# COMPUTE_CLUSTER0_MSMC_ECC_AGGR1 register map
Vendor: Texas Instruments
Peripheral module from a debugger description file (folder J7ES).
Registers are 32-bit, access not given, reset 0x0 unless marked. A register's access mark holds for its fields unless they carry their own. Offsets are as the file gives them; lines under a group give offsets from that group; [hi:lo] are bit positions; {n}, {i} and the like mark numbered series; 'fields as' and 'values as' point back to an identical list; <NAME> marks a mode.

## COMPUTE_CLUSTER0_MSMC_ECC_AGGR1
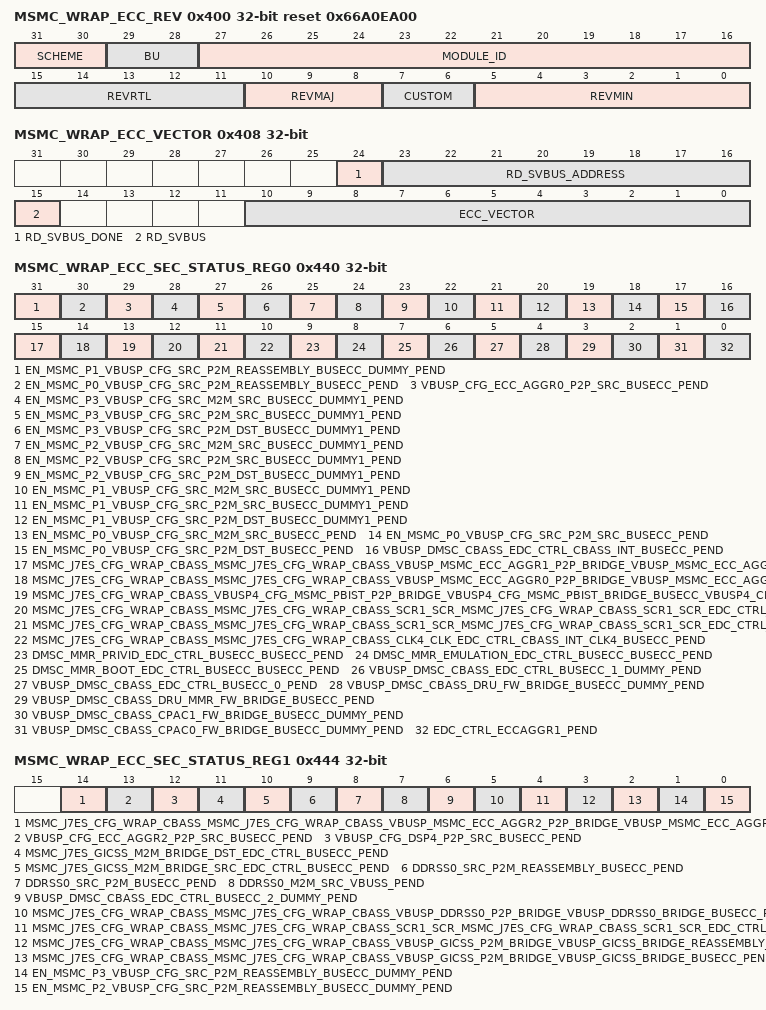
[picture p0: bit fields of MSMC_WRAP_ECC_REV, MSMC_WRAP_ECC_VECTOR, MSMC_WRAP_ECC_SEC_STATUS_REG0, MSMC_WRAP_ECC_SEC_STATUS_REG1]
0x400 MSMC_WRAP_ECC_REV ro reset 0x66A0EA00 — Revision parameters
  [31:30] SCHEME
  [29:28] BU
  [27:16] MODULE_ID
  [15:11] REVRTL — RTL version
  [10:8] REVMAJ — Major version
  [7:6] CUSTOM — Custom version
  [5:0] REVMIN — Minor version
0x408 MSMC_WRAP_ECC_VECTOR — ECC Vector Register
  [24] RD_SVBUS_DONE — Status to indicate if read on serial VBUS is complete, write of any value will clear this bit. (access RW1C)
  [23:16] RD_SVBUS_ADDRESS rw — Read address
  [15] RD_SVBUS — Write 1 to trigger a read on the serial VBUS (access RW1S)
  [10:0] ECC_VECTOR rw — Value written to select the corresponding ECC RAM for control or status
0x40C MSMC_WRAP_ECC_STAT ro reset 0x2F — Misc Status
  [10:0] NUM_RAMS — Indicates the number of RAMS serviced by the ECC aggregator
0x410 MSMC_WRAP_ECC_RESERVED_SVBUS_y rw — Reference other documents that contain the ECC RAM wrapper and EDC controller serial vbus register sets. Offset = 410h + (y * 4h); where y = 0h to 7h
  [31:0] DATA — Serial VBUS register data
0x43C MSMC_WRAP_ECC_SEC_EOI_REG — EOI Register The EOI register is used to re-trigger the pulse interrupt signal to ensure that any nested interrupt events are serviced. The software interrupt handler must write to the EOI register at the end of the current interrupt processing routine, so that new events can re-trigger the pulse interrupt signal again. For level interrupt signals the EOI register is not functional and must not be used.
  [0] EOI_WR — EOI Register (access RW1S)
0x440 MSMC_WRAP_ECC_SEC_STATUS_REG0 — Interrupt Status Register 0
  [31] EN_MSMC_P1_VBUSP_CFG_SRC_P2M_REASSEMBLY_BUSECC_DUMMY_PEND — Interrupt Pending Status for en_msmc_p1_vbusp_cfg_src_p2m_reassembly_busecc_dummy_pend (access RW1S)
  [30] EN_MSMC_P0_VBUSP_CFG_SRC_P2M_REASSEMBLY_BUSECC_PEND — Interrupt Pending Status for en_msmc_p0_vbusp_cfg_src_p2m_reassembly_busecc_pend (access RW1S)
  [29] VBUSP_CFG_ECC_AGGR0_P2P_SRC_BUSECC_PEND — Interrupt Pending Status for vbusp_cfg_ecc_aggr0_p2p_src_busecc_pend (access RW1S)
  [28] EN_MSMC_P3_VBUSP_CFG_SRC_M2M_SRC_BUSECC_DUMMY1_PEND — Interrupt Pending Status for en_msmc_p3_vbusp_cfg_src_m2m_src_busecc_dummy1_pend (access RW1S)
  [27] EN_MSMC_P3_VBUSP_CFG_SRC_P2M_SRC_BUSECC_DUMMY1_PEND — Interrupt Pending Status for en_msmc_p3_vbusp_cfg_src_p2m_src_busecc_dummy1_pend (access RW1S)
  [26] EN_MSMC_P3_VBUSP_CFG_SRC_P2M_DST_BUSECC_DUMMY1_PEND — Interrupt Pending Status for en_msmc_p3_vbusp_cfg_src_p2m_dst_busecc_dummy1_pend (access RW1S)
  [25] EN_MSMC_P2_VBUSP_CFG_SRC_M2M_SRC_BUSECC_DUMMY1_PEND — Interrupt Pending Status for en_msmc_p2_vbusp_cfg_src_m2m_src_busecc_dummy1_pend (access RW1S)
  [24] EN_MSMC_P2_VBUSP_CFG_SRC_P2M_SRC_BUSECC_DUMMY1_PEND — Interrupt Pending Status for en_msmc_p2_vbusp_cfg_src_p2m_src_busecc_dummy1_pend (access RW1S)
  [23] EN_MSMC_P2_VBUSP_CFG_SRC_P2M_DST_BUSECC_DUMMY1_PEND — Interrupt Pending Status for en_msmc_p2_vbusp_cfg_src_p2m_dst_busecc_dummy1_pend (access RW1S)
  [22] EN_MSMC_P1_VBUSP_CFG_SRC_M2M_SRC_BUSECC_DUMMY1_PEND — Interrupt Pending Status for en_msmc_p1_vbusp_cfg_src_m2m_src_busecc_dummy1_pend (access RW1S)
  [21] EN_MSMC_P1_VBUSP_CFG_SRC_P2M_SRC_BUSECC_DUMMY1_PEND — Interrupt Pending Status for en_msmc_p1_vbusp_cfg_src_p2m_src_busecc_dummy1_pend (access RW1S)
  [20] EN_MSMC_P1_VBUSP_CFG_SRC_P2M_DST_BUSECC_DUMMY1_PEND — Interrupt Pending Status for en_msmc_p1_vbusp_cfg_src_p2m_dst_busecc_dummy1_pend (access RW1S)
  [19] EN_MSMC_P0_VBUSP_CFG_SRC_M2M_SRC_BUSECC_PEND — Interrupt Pending Status for en_msmc_p0_vbusp_cfg_src_m2m_src_busecc_pend (access RW1S)
  [18] EN_MSMC_P0_VBUSP_CFG_SRC_P2M_SRC_BUSECC_PEND — Interrupt Pending Status for en_msmc_p0_vbusp_cfg_src_p2m_src_busecc_pend (access RW1S)
  [17] EN_MSMC_P0_VBUSP_CFG_SRC_P2M_DST_BUSECC_PEND — Interrupt Pending Status for en_msmc_p0_vbusp_cfg_src_p2m_dst_busecc_pend (access RW1S)
  [16] VBUSP_DMSC_CBASS_EDC_CTRL_CBASS_INT_BUSECC_PEND — Interrupt Pending Status for vbusp_dmsc_cbass_edc_ctrl_cbass_int_busecc_pend (access RW1S)
  [15] MSMC_J7ES_CFG_WRAP_CBASS_MSMC_J7ES_CFG_WRAP_CBASS_VBUSP_MSMC_ECC_AGGR1_P2P_BRIDGE_VBUSP_MSMC_ECC_AGGR1_BRIDGE_BUSECC_PEND — Interrupt Pending Status for msmc_cfg_wrap_cbass_msmc_cfg_wrap_cbass_vbusp_msmc_ecc_aggr1_p2p_bridge_vbusp_msmc_ecc_aggr1_bridge_busecc_pend (access RW1S)
  [14] MSMC_J7ES_CFG_WRAP_CBASS_MSMC_J7ES_CFG_WRAP_CBASS_VBUSP_MSMC_ECC_AGGR0_P2P_BRIDGE_VBUSP_MSMC_ECC_AGGR0_BRIDGE_BUSECC_PEND — Interrupt Pending Status for msmc_cfg_wrap_cbass_msmc_cfg_wrap_cbass_vbusp_msmc_ecc_aggr0_p2p_bridge_vbusp_msmc_ecc_aggr0_bridge_busecc_pend (access RW1S)
  [13] MSMC_J7ES_CFG_WRAP_CBASS_VBUSP4_CFG_MSMC_PBIST_P2P_BRIDGE_VBUSP4_CFG_MSMC_PBIST_BRIDGE_BUSECC_VBUSP4_CFG_MSMC_PBIST_BRIDGE_BUSECC_DUMMY_PEND — Interrupt Pending Status for msmc_cfg_wrap_cbass_vbusp4_cfg_msmc_pbist_p2p_bridge_vbusp4_cfg_msmc_pbist_bridge_busecc_vbusp4_cfg_msmc_pbist_bridge_busecc_dummy_pend (access RW1S)
  [12] MSMC_J7ES_CFG_WRAP_CBASS_MSMC_J7ES_CFG_WRAP_CBASS_SCR1_SCR_MSMC_J7ES_CFG_WRAP_CBASS_SCR1_SCR_EDC_CTRL_BUSECC_1_DUMMY_PEND — Interrupt Pending Status for msmc_cfg_wrap_cbass_msmc_cfg_wrap_cbass_scr1_scr_msmc_cfg_wrap_cbass_scr1_scr_edc_ctrl_busecc_1_dummy_pend (access RW1S)
  [11] MSMC_J7ES_CFG_WRAP_CBASS_MSMC_J7ES_CFG_WRAP_CBASS_SCR1_SCR_MSMC_J7ES_CFG_WRAP_CBASS_SCR1_SCR_EDC_CTRL_BUSECC_PEND — Interrupt Pending Status for msmc_cfg_wrap_cbass_msmc_cfg_wrap_cbass_scr1_scr_msmc_cfg_wrap_cbass_scr1_scr_edc_ctrl_busecc_pend (access RW1S)
  [10] MSMC_J7ES_CFG_WRAP_CBASS_MSMC_J7ES_CFG_WRAP_CBASS_CLK4_CLK_EDC_CTRL_CBASS_INT_CLK4_BUSECC_PEND — Interrupt Pending Status for msmc_cfg_wrap_cbass_msmc_cfg_wrap_cbass_clk4_clk_edc_ctrl_cbass_int_clk4_busecc_pend (access RW1S)
  [9] DMSC_MMR_PRIVID_EDC_CTRL_BUSECC_BUSECC_PEND — Interrupt Pending Status for dmsc_mmr_privid_edc_ctrl_busecc_busecc_pend (access RW1S)
  [8] DMSC_MMR_EMULATION_EDC_CTRL_BUSECC_BUSECC_PEND — Interrupt Pending Status for dmsc_mmr_emulation_edc_ctrl_busecc_busecc_pend (access RW1S)
  [7] DMSC_MMR_BOOT_EDC_CTRL_BUSECC_BUSECC_PEND — Interrupt Pending Status for dmsc_mmr_boot_edc_ctrl_busecc_busecc_pend (access RW1S)
  [6] VBUSP_DMSC_CBASS_EDC_CTRL_BUSECC_1_DUMMY_PEND — Interrupt Pending Status for vbusp_dmsc_cbass_edc_ctrl_busecc_1_dummy_pend (access RW1S)
  [5] VBUSP_DMSC_CBASS_EDC_CTRL_BUSECC_0_PEND — Interrupt Pending Status for vbusp_dmsc_cbass_edc_ctrl_busecc_0_pend (access RW1S)
  [4] VBUSP_DMSC_CBASS_DRU_FW_BRIDGE_BUSECC_DUMMY_PEND — Interrupt Pending Status for vbusp_dmsc_cbass_dru_fw_bridge_busecc_dummy_pend (access RW1S)
  [3] VBUSP_DMSC_CBASS_DRU_MMR_FW_BRIDGE_BUSECC_PEND — Interrupt Pending Status for vbusp_dmsc_cbass_dru_mmr_fw_bridge_busecc_pend (access RW1S)
  [2] VBUSP_DMSC_CBASS_CPAC1_FW_BRIDGE_BUSECC_DUMMY_PEND — Interrupt Pending Status for vbusp_dmsc_cbass_cpac1_fw_bridge_busecc_dummy_pend (access RW1S)
  [1] VBUSP_DMSC_CBASS_CPAC0_FW_BRIDGE_BUSECC_DUMMY_PEND — Interrupt Pending Status for vbusp_dmsc_cbass_cpac0_fw_bridge_busecc_dummy_pend (access RW1S)
  [0] EDC_CTRL_ECCAGGR1_PEND — Interrupt Pending Status for edc_ctrl_eccaggr1_pend (access RW1S)
0x444 MSMC_WRAP_ECC_SEC_STATUS_REG1 — Interrupt Status Register 1
  [14] MSMC_J7ES_CFG_WRAP_CBASS_MSMC_J7ES_CFG_WRAP_CBASS_VBUSP_MSMC_ECC_AGGR2_P2P_BRIDGE_VBUSP_MSMC_ECC_AGGR2_BRIDGE_BUSECC_PEND — Interrupt Pending Status for msmc_cfg_wrap_cbass_msmc_cfg_wrap_cbass_vbusp_msmc_ecc_aggr2_p2p_bridge_vbusp_msmc_ecc_aggr2_bridge_busecc_pend (access RW1S)
  [13] VBUSP_CFG_ECC_AGGR2_P2P_SRC_BUSECC_PEND — Interrupt Pending Status for vbusp_cfg_ecc_aggr2_p2p_src_busecc_pend (access RW1S)
  [12] VBUSP_CFG_DSP4_P2P_SRC_BUSECC_PEND — Interrupt Pending Status for vbusp_cfg_dsp4_p2p_src_busecc_pend (access RW1S)
  [11] MSMC_J7ES_GICSS_M2M_BRIDGE_DST_EDC_CTRL_BUSECC_PEND — Interrupt Pending Status for msmc_gicss_m2m_bridge_dst_edc_ctrl_busecc_pend (access RW1S)
  [10] MSMC_J7ES_GICSS_M2M_BRIDGE_SRC_EDC_CTRL_BUSECC_PEND — Interrupt Pending Status for msmc_gicss_m2m_bridge_src_edc_ctrl_busecc_pend (access RW1S)
  [9] DDRSS0_SRC_P2M_REASSEMBLY_BUSECC_PEND — Interrupt Pending Status for ddrss0_src_p2m_reassembly_busecc_pend (access RW1S)
  [8] DDRSS0_SRC_P2M_BUSECC_PEND — Interrupt Pending Status for ddrss0_src_p2m_busecc_pend (access RW1S)
  [7] DDRSS0_M2M_SRC_VBUSS_PEND — Interrupt Pending Status for ddrss0_m2m_src_vbuss_pend (access RW1S)
  [6] VBUSP_DMSC_CBASS_EDC_CTRL_BUSECC_2_DUMMY_PEND — Interrupt Pending Status for vbusp_dmsc_cbass_edc_ctrl_busecc_2_dummy_pend (access RW1S)
  [5] MSMC_J7ES_CFG_WRAP_CBASS_MSMC_J7ES_CFG_WRAP_CBASS_VBUSP_DDRSS0_P2P_BRIDGE_VBUSP_DDRSS0_BRIDGE_BUSECC_PEND — Interrupt Pending Status for msmc_cfg_wrap_cbass_msmc_cfg_wrap_cbass_vbusp_ddrss0_p2p_bridge_vbusp_ddrss0_bridge_busecc_pend (access RW1S)
  [4] MSMC_J7ES_CFG_WRAP_CBASS_MSMC_J7ES_CFG_WRAP_CBASS_SCR1_SCR_MSMC_J7ES_CFG_WRAP_CBASS_SCR1_SCR_EDC_CTRL_BUSECC_2_DUMMY_PEND — Interrupt Pending Status for msmc_cfg_wrap_cbass_msmc_cfg_wrap_cbass_scr1_scr_msmc_cfg_wrap_cbass_scr1_scr_edc_ctrl_busecc_2_dummy_pend (access RW1S)
  [3] MSMC_J7ES_CFG_WRAP_CBASS_MSMC_J7ES_CFG_WRAP_CBASS_VBUSP_GICSS_P2M_BRIDGE_VBUSP_GICSS_BRIDGE_REASSEMBLY_BUSECC_PEND — Interrupt Pending Status for msmc_cfg_wrap_cbass_msmc_cfg_wrap_cbass_vbusp_gicss_p2m_bridge_vbusp_gicss_bridge_reassembly_busecc_pend (access RW1S)
  [2] MSMC_J7ES_CFG_WRAP_CBASS_MSMC_J7ES_CFG_WRAP_CBASS_VBUSP_GICSS_P2M_BRIDGE_VBUSP_GICSS_BRIDGE_BUSECC_PEND — Interrupt Pending Status for msmc_cfg_wrap_cbass_msmc_cfg_wrap_cbass_vbusp_gicss_p2m_bridge_vbusp_gicss_bridge_busecc_pend (access RW1S)
  [1] EN_MSMC_P3_VBUSP_CFG_SRC_P2M_REASSEMBLY_BUSECC_DUMMY_PEND — Interrupt Pending Status for en_msmc_p3_vbusp_cfg_src_p2m_reassembly_busecc_dummy_pend (access RW1S)
  [0] EN_MSMC_P2_VBUSP_CFG_SRC_P2M_REASSEMBLY_BUSECC_DUMMY_PEND — Interrupt Pending Status for en_msmc_p2_vbusp_cfg_src_p2m_reassembly_busecc_dummy_pend (access RW1S)
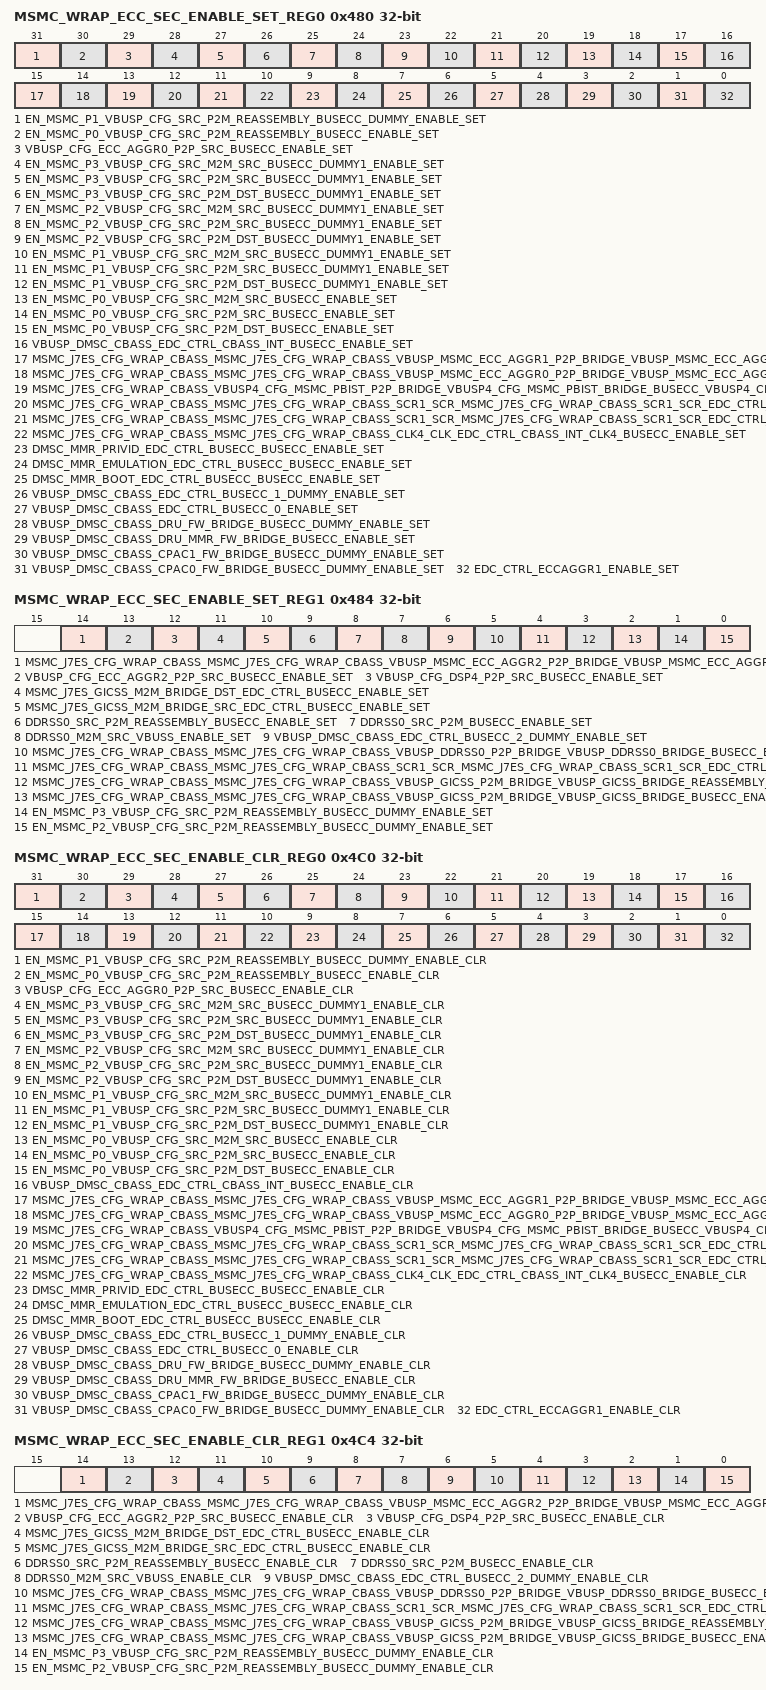
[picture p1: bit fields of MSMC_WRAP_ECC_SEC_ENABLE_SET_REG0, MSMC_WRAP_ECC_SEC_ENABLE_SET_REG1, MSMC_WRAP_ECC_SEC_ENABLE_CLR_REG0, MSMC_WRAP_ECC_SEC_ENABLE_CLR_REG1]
0x480 MSMC_WRAP_ECC_SEC_ENABLE_SET_REG0 — Interrupt Enable Set Register 0
  [31] EN_MSMC_P1_VBUSP_CFG_SRC_P2M_REASSEMBLY_BUSECC_DUMMY_ENABLE_SET — Interrupt Enable Set Register for en_msmc_p1_vbusp_cfg_src_p2m_reassembly_busecc_dummy_pend (access RW1S)
  [30] EN_MSMC_P0_VBUSP_CFG_SRC_P2M_REASSEMBLY_BUSECC_ENABLE_SET — Interrupt Enable Set Register for en_msmc_p0_vbusp_cfg_src_p2m_reassembly_busecc_pend (access RW1S)
  [29] VBUSP_CFG_ECC_AGGR0_P2P_SRC_BUSECC_ENABLE_SET — Interrupt Enable Set Register for vbusp_cfg_ecc_aggr0_p2p_src_busecc_pend (access RW1S)
  [28] EN_MSMC_P3_VBUSP_CFG_SRC_M2M_SRC_BUSECC_DUMMY1_ENABLE_SET — Interrupt Enable Set Register for en_msmc_p3_vbusp_cfg_src_m2m_src_busecc_dummy1_pend (access RW1S)
  [27] EN_MSMC_P3_VBUSP_CFG_SRC_P2M_SRC_BUSECC_DUMMY1_ENABLE_SET — Interrupt Enable Set Register for en_msmc_p3_vbusp_cfg_src_p2m_src_busecc_dummy1_pend (access RW1S)
  [26] EN_MSMC_P3_VBUSP_CFG_SRC_P2M_DST_BUSECC_DUMMY1_ENABLE_SET — Interrupt Enable Set Register for en_msmc_p3_vbusp_cfg_src_p2m_dst_busecc_dummy1_pend (access RW1S)
  [25] EN_MSMC_P2_VBUSP_CFG_SRC_M2M_SRC_BUSECC_DUMMY1_ENABLE_SET — Interrupt Enable Set Register for en_msmc_p2_vbusp_cfg_src_m2m_src_busecc_dummy1_pend (access RW1S)
  [24] EN_MSMC_P2_VBUSP_CFG_SRC_P2M_SRC_BUSECC_DUMMY1_ENABLE_SET — Interrupt Enable Set Register for en_msmc_p2_vbusp_cfg_src_p2m_src_busecc_dummy1_pend (access RW1S)
  [23] EN_MSMC_P2_VBUSP_CFG_SRC_P2M_DST_BUSECC_DUMMY1_ENABLE_SET — Interrupt Enable Set Register for en_msmc_p2_vbusp_cfg_src_p2m_dst_busecc_dummy1_pend (access RW1S)
  [22] EN_MSMC_P1_VBUSP_CFG_SRC_M2M_SRC_BUSECC_DUMMY1_ENABLE_SET — Interrupt Enable Set Register for en_msmc_p1_vbusp_cfg_src_m2m_src_busecc_dummy1_pend (access RW1S)
  [21] EN_MSMC_P1_VBUSP_CFG_SRC_P2M_SRC_BUSECC_DUMMY1_ENABLE_SET — Interrupt Enable Set Register for en_msmc_p1_vbusp_cfg_src_p2m_src_busecc_dummy1_pend (access RW1S)
  [20] EN_MSMC_P1_VBUSP_CFG_SRC_P2M_DST_BUSECC_DUMMY1_ENABLE_SET — Interrupt Enable Set Register for en_msmc_p1_vbusp_cfg_src_p2m_dst_busecc_dummy1_pend (access RW1S)
  [19] EN_MSMC_P0_VBUSP_CFG_SRC_M2M_SRC_BUSECC_ENABLE_SET — Interrupt Enable Set Register for en_msmc_p0_vbusp_cfg_src_m2m_src_busecc_pend (access RW1S)
  [18] EN_MSMC_P0_VBUSP_CFG_SRC_P2M_SRC_BUSECC_ENABLE_SET — Interrupt Enable Set Register for en_msmc_p0_vbusp_cfg_src_p2m_src_busecc_pend (access RW1S)
  [17] EN_MSMC_P0_VBUSP_CFG_SRC_P2M_DST_BUSECC_ENABLE_SET — Interrupt Enable Set Register for en_msmc_p0_vbusp_cfg_src_p2m_dst_busecc_pend (access RW1S)
  [16] VBUSP_DMSC_CBASS_EDC_CTRL_CBASS_INT_BUSECC_ENABLE_SET — Interrupt Enable Set Register for vbusp_dmsc_cbass_edc_ctrl_cbass_int_busecc_pend (access RW1S)
  [15] MSMC_J7ES_CFG_WRAP_CBASS_MSMC_J7ES_CFG_WRAP_CBASS_VBUSP_MSMC_ECC_AGGR1_P2P_BRIDGE_VBUSP_MSMC_ECC_AGGR1_BRIDGE_BUSECC_ENABLE_SET — Interrupt Enable Set Register for msmc_cfg_wrap_cbass_msmc_cfg_wrap_cbass_vbusp_msmc_ecc_aggr1_p2p_bridge_vbusp_msmc_ecc_aggr1_bridge_busecc_pend (access RW1S)
  [14] MSMC_J7ES_CFG_WRAP_CBASS_MSMC_J7ES_CFG_WRAP_CBASS_VBUSP_MSMC_ECC_AGGR0_P2P_BRIDGE_VBUSP_MSMC_ECC_AGGR0_BRIDGE_BUSECC_ENABLE_SET — Interrupt Enable Set Register for msmc_cfg_wrap_cbass_msmc_cfg_wrap_cbass_vbusp_msmc_ecc_aggr0_p2p_bridge_vbusp_msmc_ecc_aggr0_bridge_busecc_pend (access RW1S)
  [13] MSMC_J7ES_CFG_WRAP_CBASS_VBUSP4_CFG_MSMC_PBIST_P2P_BRIDGE_VBUSP4_CFG_MSMC_PBIST_BRIDGE_BUSECC_VBUSP4_CFG_MSMC_PBIST_BRIDGE_BUSECC_DUMMY_ENABLE_SET — Interrupt Enable Set Register for msmc_cfg_wrap_cbass_vbusp4_cfg_msmc_pbist_p2p_bridge_vbusp4_cfg_msmc_pbist_bridge_busecc_vbusp4_cfg_msmc_pbist_bridge_busecc_dummy_pend (access RW1S)
  [12] MSMC_J7ES_CFG_WRAP_CBASS_MSMC_J7ES_CFG_WRAP_CBASS_SCR1_SCR_MSMC_J7ES_CFG_WRAP_CBASS_SCR1_SCR_EDC_CTRL_BUSECC_1_DUMMY_ENABLE_SET — Interrupt Enable Set Register for msmc_cfg_wrap_cbass_msmc_cfg_wrap_cbass_scr1_scr_msmc_cfg_wrap_cbass_scr1_scr_edc_ctrl_busecc_1_dummy_pend (access RW1S)
  [11] MSMC_J7ES_CFG_WRAP_CBASS_MSMC_J7ES_CFG_WRAP_CBASS_SCR1_SCR_MSMC_J7ES_CFG_WRAP_CBASS_SCR1_SCR_EDC_CTRL_BUSECC_ENABLE_SET — Interrupt Enable Set Register for msmc_cfg_wrap_cbass_msmc_cfg_wrap_cbass_scr1_scr_msmc_cfg_wrap_cbass_scr1_scr_edc_ctrl_busecc_pend (access RW1S)
  [10] MSMC_J7ES_CFG_WRAP_CBASS_MSMC_J7ES_CFG_WRAP_CBASS_CLK4_CLK_EDC_CTRL_CBASS_INT_CLK4_BUSECC_ENABLE_SET — Interrupt Enable Set Register for msmc_cfg_wrap_cbass_msmc_cfg_wrap_cbass_clk4_clk_edc_ctrl_cbass_int_clk4_busecc_pend (access RW1S)
  [9] DMSC_MMR_PRIVID_EDC_CTRL_BUSECC_BUSECC_ENABLE_SET — Interrupt Enable Set Register for dmsc_mmr_privid_edc_ctrl_busecc_busecc_pend (access RW1S)
  [8] DMSC_MMR_EMULATION_EDC_CTRL_BUSECC_BUSECC_ENABLE_SET — Interrupt Enable Set Register for dmsc_mmr_emulation_edc_ctrl_busecc_busecc_pend (access RW1S)
  [7] DMSC_MMR_BOOT_EDC_CTRL_BUSECC_BUSECC_ENABLE_SET — Interrupt Enable Set Register for dmsc_mmr_boot_edc_ctrl_busecc_busecc_pend (access RW1S)
  [6] VBUSP_DMSC_CBASS_EDC_CTRL_BUSECC_1_DUMMY_ENABLE_SET — Interrupt Enable Set Register for vbusp_dmsc_cbass_edc_ctrl_busecc_1_dummy_pend (access RW1S)
  [5] VBUSP_DMSC_CBASS_EDC_CTRL_BUSECC_0_ENABLE_SET — Interrupt Enable Set Register for vbusp_dmsc_cbass_edc_ctrl_busecc_0_pend (access RW1S)
  [4] VBUSP_DMSC_CBASS_DRU_FW_BRIDGE_BUSECC_DUMMY_ENABLE_SET — Interrupt Enable Set Register for vbusp_dmsc_cbass_dru_fw_bridge_busecc_dummy_pend (access RW1S)
  [3] VBUSP_DMSC_CBASS_DRU_MMR_FW_BRIDGE_BUSECC_ENABLE_SET — Interrupt Enable Set Register for vbusp_dmsc_cbass_dru_mmr_fw_bridge_busecc_pend (access RW1S)
  [2] VBUSP_DMSC_CBASS_CPAC1_FW_BRIDGE_BUSECC_DUMMY_ENABLE_SET — Interrupt Enable Set Register for vbusp_dmsc_cbass_cpac1_fw_bridge_busecc_dummy_pend (access RW1S)
  [1] VBUSP_DMSC_CBASS_CPAC0_FW_BRIDGE_BUSECC_DUMMY_ENABLE_SET — Interrupt Enable Set Register for vbusp_dmsc_cbass_cpac0_fw_bridge_busecc_dummy_pend (access RW1S)
  [0] EDC_CTRL_ECCAGGR1_ENABLE_SET — Interrupt Enable Set Register for edc_ctrl_eccaggr1_pend (access RW1S)
0x484 MSMC_WRAP_ECC_SEC_ENABLE_SET_REG1 — Interrupt Enable Set Register 1
  [14] MSMC_J7ES_CFG_WRAP_CBASS_MSMC_J7ES_CFG_WRAP_CBASS_VBUSP_MSMC_ECC_AGGR2_P2P_BRIDGE_VBUSP_MSMC_ECC_AGGR2_BRIDGE_BUSECC_ENABLE_SET — Interrupt Enable Set Register for msmc_cfg_wrap_cbass_msmc_cfg_wrap_cbass_vbusp_msmc_ecc_aggr2_p2p_bridge_vbusp_msmc_ecc_aggr2_bridge_busecc_pend (access RW1S)
  [13] VBUSP_CFG_ECC_AGGR2_P2P_SRC_BUSECC_ENABLE_SET — Interrupt Enable Set Register for vbusp_cfg_ecc_aggr2_p2p_src_busecc_pend (access RW1S)
  [12] VBUSP_CFG_DSP4_P2P_SRC_BUSECC_ENABLE_SET — Interrupt Enable Set Register for vbusp_cfg_dsp4_p2p_src_busecc_pend (access RW1S)
  [11] MSMC_J7ES_GICSS_M2M_BRIDGE_DST_EDC_CTRL_BUSECC_ENABLE_SET — Interrupt Enable Set Register for msmc_gicss_m2m_bridge_dst_edc_ctrl_busecc_pend (access RW1S)
  [10] MSMC_J7ES_GICSS_M2M_BRIDGE_SRC_EDC_CTRL_BUSECC_ENABLE_SET — Interrupt Enable Set Register for msmc_gicss_m2m_bridge_src_edc_ctrl_busecc_pend (access RW1S)
  [9] DDRSS0_SRC_P2M_REASSEMBLY_BUSECC_ENABLE_SET — Interrupt Enable Set Register for ddrss0_src_p2m_reassembly_busecc_pend (access RW1S)
  [8] DDRSS0_SRC_P2M_BUSECC_ENABLE_SET — Interrupt Enable Set Register for ddrss0_src_p2m_busecc_pend (access RW1S)
  [7] DDRSS0_M2M_SRC_VBUSS_ENABLE_SET — Interrupt Enable Set Register for ddrss0_m2m_src_vbuss_pend (access RW1S)
  [6] VBUSP_DMSC_CBASS_EDC_CTRL_BUSECC_2_DUMMY_ENABLE_SET — Interrupt Enable Set Register for vbusp_dmsc_cbass_edc_ctrl_busecc_2_dummy_pend (access RW1S)
  [5] MSMC_J7ES_CFG_WRAP_CBASS_MSMC_J7ES_CFG_WRAP_CBASS_VBUSP_DDRSS0_P2P_BRIDGE_VBUSP_DDRSS0_BRIDGE_BUSECC_ENABLE_SET — Interrupt Enable Set Register for msmc_cfg_wrap_cbass_msmc_cfg_wrap_cbass_vbusp_ddrss0_p2p_bridge_vbusp_ddrss0_bridge_busecc_pend (access RW1S)
  [4] MSMC_J7ES_CFG_WRAP_CBASS_MSMC_J7ES_CFG_WRAP_CBASS_SCR1_SCR_MSMC_J7ES_CFG_WRAP_CBASS_SCR1_SCR_EDC_CTRL_BUSECC_2_DUMMY_ENABLE_SET — Interrupt Enable Set Register for msmc_cfg_wrap_cbass_msmc_cfg_wrap_cbass_scr1_scr_msmc_cfg_wrap_cbass_scr1_scr_edc_ctrl_busecc_2_dummy_pend (access RW1S)
  [3] MSMC_J7ES_CFG_WRAP_CBASS_MSMC_J7ES_CFG_WRAP_CBASS_VBUSP_GICSS_P2M_BRIDGE_VBUSP_GICSS_BRIDGE_REASSEMBLY_BUSECC_ENABLE_SET — Interrupt Enable Set Register for msmc_cfg_wrap_cbass_msmc_cfg_wrap_cbass_vbusp_gicss_p2m_bridge_vbusp_gicss_bridge_reassembly_busecc_pend (access RW1S)
  [2] MSMC_J7ES_CFG_WRAP_CBASS_MSMC_J7ES_CFG_WRAP_CBASS_VBUSP_GICSS_P2M_BRIDGE_VBUSP_GICSS_BRIDGE_BUSECC_ENABLE_SET — Interrupt Enable Set Register for msmc_cfg_wrap_cbass_msmc_cfg_wrap_cbass_vbusp_gicss_p2m_bridge_vbusp_gicss_bridge_busecc_pend (access RW1S)
  [1] EN_MSMC_P3_VBUSP_CFG_SRC_P2M_REASSEMBLY_BUSECC_DUMMY_ENABLE_SET — Interrupt Enable Set Register for en_msmc_p3_vbusp_cfg_src_p2m_reassembly_busecc_dummy_pend (access RW1S)
  [0] EN_MSMC_P2_VBUSP_CFG_SRC_P2M_REASSEMBLY_BUSECC_DUMMY_ENABLE_SET — Interrupt Enable Set Register for en_msmc_p2_vbusp_cfg_src_p2m_reassembly_busecc_dummy_pend (access RW1S)
0x4C0 MSMC_WRAP_ECC_SEC_ENABLE_CLR_REG0 — Interrupt Enable Clear Register 0
  [31] EN_MSMC_P1_VBUSP_CFG_SRC_P2M_REASSEMBLY_BUSECC_DUMMY_ENABLE_CLR — Interrupt Enable Clear Register for en_msmc_p1_vbusp_cfg_src_p2m_reassembly_busecc_dummy_pend (access RW1C)
  [30] EN_MSMC_P0_VBUSP_CFG_SRC_P2M_REASSEMBLY_BUSECC_ENABLE_CLR — Interrupt Enable Clear Register for en_msmc_p0_vbusp_cfg_src_p2m_reassembly_busecc_pend (access RW1C)
  [29] VBUSP_CFG_ECC_AGGR0_P2P_SRC_BUSECC_ENABLE_CLR — Interrupt Enable Clear Register for vbusp_cfg_ecc_aggr0_p2p_src_busecc_pend (access RW1C)
  [28] EN_MSMC_P3_VBUSP_CFG_SRC_M2M_SRC_BUSECC_DUMMY1_ENABLE_CLR — Interrupt Enable Clear Register for en_msmc_p3_vbusp_cfg_src_m2m_src_busecc_dummy1_pend (access RW1C)
  [27] EN_MSMC_P3_VBUSP_CFG_SRC_P2M_SRC_BUSECC_DUMMY1_ENABLE_CLR — Interrupt Enable Clear Register for en_msmc_p3_vbusp_cfg_src_p2m_src_busecc_dummy1_pend (access RW1C)
  [26] EN_MSMC_P3_VBUSP_CFG_SRC_P2M_DST_BUSECC_DUMMY1_ENABLE_CLR — Interrupt Enable Clear Register for en_msmc_p3_vbusp_cfg_src_p2m_dst_busecc_dummy1_pend (access RW1C)
  [25] EN_MSMC_P2_VBUSP_CFG_SRC_M2M_SRC_BUSECC_DUMMY1_ENABLE_CLR — Interrupt Enable Clear Register for en_msmc_p2_vbusp_cfg_src_m2m_src_busecc_dummy1_pend (access RW1C)
  [24] EN_MSMC_P2_VBUSP_CFG_SRC_P2M_SRC_BUSECC_DUMMY1_ENABLE_CLR — Interrupt Enable Clear Register for en_msmc_p2_vbusp_cfg_src_p2m_src_busecc_dummy1_pend (access RW1C)
  [23] EN_MSMC_P2_VBUSP_CFG_SRC_P2M_DST_BUSECC_DUMMY1_ENABLE_CLR — Interrupt Enable Clear Register for en_msmc_p2_vbusp_cfg_src_p2m_dst_busecc_dummy1_pend (access RW1C)
  [22] EN_MSMC_P1_VBUSP_CFG_SRC_M2M_SRC_BUSECC_DUMMY1_ENABLE_CLR — Interrupt Enable Clear Register for en_msmc_p1_vbusp_cfg_src_m2m_src_busecc_dummy1_pend (access RW1C)
  [21] EN_MSMC_P1_VBUSP_CFG_SRC_P2M_SRC_BUSECC_DUMMY1_ENABLE_CLR — Interrupt Enable Clear Register for en_msmc_p1_vbusp_cfg_src_p2m_src_busecc_dummy1_pend (access RW1C)
  [20] EN_MSMC_P1_VBUSP_CFG_SRC_P2M_DST_BUSECC_DUMMY1_ENABLE_CLR — Interrupt Enable Clear Register for en_msmc_p1_vbusp_cfg_src_p2m_dst_busecc_dummy1_pend (access RW1C)
  [19] EN_MSMC_P0_VBUSP_CFG_SRC_M2M_SRC_BUSECC_ENABLE_CLR — Interrupt Enable Clear Register for en_msmc_p0_vbusp_cfg_src_m2m_src_busecc_pend (access RW1C)
  [18] EN_MSMC_P0_VBUSP_CFG_SRC_P2M_SRC_BUSECC_ENABLE_CLR — Interrupt Enable Clear Register for en_msmc_p0_vbusp_cfg_src_p2m_src_busecc_pend (access RW1C)
  [17] EN_MSMC_P0_VBUSP_CFG_SRC_P2M_DST_BUSECC_ENABLE_CLR — Interrupt Enable Clear Register for en_msmc_p0_vbusp_cfg_src_p2m_dst_busecc_pend (access RW1C)
  [16] VBUSP_DMSC_CBASS_EDC_CTRL_CBASS_INT_BUSECC_ENABLE_CLR — Interrupt Enable Clear Register for vbusp_dmsc_cbass_edc_ctrl_cbass_int_busecc_pend (access RW1C)
  [15] MSMC_J7ES_CFG_WRAP_CBASS_MSMC_J7ES_CFG_WRAP_CBASS_VBUSP_MSMC_ECC_AGGR1_P2P_BRIDGE_VBUSP_MSMC_ECC_AGGR1_BRIDGE_BUSECC_ENABLE_CLR — Interrupt Enable Clear Register for msmc_cfg_wrap_cbass_msmc_cfg_wrap_cbass_vbusp_msmc_ecc_aggr1_p2p_bridge_vbusp_msmc_ecc_aggr1_bridge_busecc_pend (access RW1C)
  [14] MSMC_J7ES_CFG_WRAP_CBASS_MSMC_J7ES_CFG_WRAP_CBASS_VBUSP_MSMC_ECC_AGGR0_P2P_BRIDGE_VBUSP_MSMC_ECC_AGGR0_BRIDGE_BUSECC_ENABLE_CLR — Interrupt Enable Clear Register for msmc_cfg_wrap_cbass_msmc_cfg_wrap_cbass_vbusp_msmc_ecc_aggr0_p2p_bridge_vbusp_msmc_ecc_aggr0_bridge_busecc_pend (access RW1C)
  [13] MSMC_J7ES_CFG_WRAP_CBASS_VBUSP4_CFG_MSMC_PBIST_P2P_BRIDGE_VBUSP4_CFG_MSMC_PBIST_BRIDGE_BUSECC_VBUSP4_CFG_MSMC_PBIST_BRIDGE_BUSECC_DUMMY_ENABLE_CLR — Interrupt Enable Clear Register for msmc_cfg_wrap_cbass_vbusp4_cfg_msmc_pbist_p2p_bridge_vbusp4_cfg_msmc_pbist_bridge_busecc_vbusp4_cfg_msmc_pbist_bridge_busecc_dummy_pend (access RW1C)
  [12] MSMC_J7ES_CFG_WRAP_CBASS_MSMC_J7ES_CFG_WRAP_CBASS_SCR1_SCR_MSMC_J7ES_CFG_WRAP_CBASS_SCR1_SCR_EDC_CTRL_BUSECC_1_DUMMY_ENABLE_CLR — Interrupt Enable Clear Register for msmc_cfg_wrap_cbass_msmc_cfg_wrap_cbass_scr1_scr_msmc_cfg_wrap_cbass_scr1_scr_edc_ctrl_busecc_1_dummy_pend (access RW1C)
  [11] MSMC_J7ES_CFG_WRAP_CBASS_MSMC_J7ES_CFG_WRAP_CBASS_SCR1_SCR_MSMC_J7ES_CFG_WRAP_CBASS_SCR1_SCR_EDC_CTRL_BUSECC_ENABLE_CLR — Interrupt Enable Clear Register for msmc_cfg_wrap_cbass_msmc_cfg_wrap_cbass_scr1_scr_msmc_cfg_wrap_cbass_scr1_scr_edc_ctrl_busecc_pend (access RW1C)
  [10] MSMC_J7ES_CFG_WRAP_CBASS_MSMC_J7ES_CFG_WRAP_CBASS_CLK4_CLK_EDC_CTRL_CBASS_INT_CLK4_BUSECC_ENABLE_CLR — Interrupt Enable Clear Register for msmc_cfg_wrap_cbass_msmc_cfg_wrap_cbass_clk4_clk_edc_ctrl_cbass_int_clk4_busecc_pend (access RW1C)
  [9] DMSC_MMR_PRIVID_EDC_CTRL_BUSECC_BUSECC_ENABLE_CLR — Interrupt Enable Clear Register for dmsc_mmr_privid_edc_ctrl_busecc_busecc_pend (access RW1C)
  [8] DMSC_MMR_EMULATION_EDC_CTRL_BUSECC_BUSECC_ENABLE_CLR — Interrupt Enable Clear Register for dmsc_mmr_emulation_edc_ctrl_busecc_busecc_pend (access RW1C)
  [7] DMSC_MMR_BOOT_EDC_CTRL_BUSECC_BUSECC_ENABLE_CLR — Interrupt Enable Clear Register for dmsc_mmr_boot_edc_ctrl_busecc_busecc_pend (access RW1C)
  [6] VBUSP_DMSC_CBASS_EDC_CTRL_BUSECC_1_DUMMY_ENABLE_CLR — Interrupt Enable Clear Register for vbusp_dmsc_cbass_edc_ctrl_busecc_1_dummy_pend (access RW1C)
  [5] VBUSP_DMSC_CBASS_EDC_CTRL_BUSECC_0_ENABLE_CLR — Interrupt Enable Clear Register for vbusp_dmsc_cbass_edc_ctrl_busecc_0_pend (access RW1C)
  [4] VBUSP_DMSC_CBASS_DRU_FW_BRIDGE_BUSECC_DUMMY_ENABLE_CLR — Interrupt Enable Clear Register for vbusp_dmsc_cbass_dru_fw_bridge_busecc_dummy_pend (access RW1C)
  [3] VBUSP_DMSC_CBASS_DRU_MMR_FW_BRIDGE_BUSECC_ENABLE_CLR — Interrupt Enable Clear Register for vbusp_dmsc_cbass_dru_mmr_fw_bridge_busecc_pend (access RW1C)
  [2] VBUSP_DMSC_CBASS_CPAC1_FW_BRIDGE_BUSECC_DUMMY_ENABLE_CLR — Interrupt Enable Clear Register for vbusp_dmsc_cbass_cpac1_fw_bridge_busecc_dummy_pend (access RW1C)
  [1] VBUSP_DMSC_CBASS_CPAC0_FW_BRIDGE_BUSECC_DUMMY_ENABLE_CLR — Interrupt Enable Clear Register for vbusp_dmsc_cbass_cpac0_fw_bridge_busecc_dummy_pend (access RW1C)
  [0] EDC_CTRL_ECCAGGR1_ENABLE_CLR — Interrupt Enable Clear Register for edc_ctrl_eccaggr1_pend (access RW1C)
0x4C4 MSMC_WRAP_ECC_SEC_ENABLE_CLR_REG1 — Interrupt Enable Clear Register 1
  [14] MSMC_J7ES_CFG_WRAP_CBASS_MSMC_J7ES_CFG_WRAP_CBASS_VBUSP_MSMC_ECC_AGGR2_P2P_BRIDGE_VBUSP_MSMC_ECC_AGGR2_BRIDGE_BUSECC_ENABLE_CLR — Interrupt Enable Clear Register for msmc_cfg_wrap_cbass_msmc_cfg_wrap_cbass_vbusp_msmc_ecc_aggr2_p2p_bridge_vbusp_msmc_ecc_aggr2_bridge_busecc_pend (access RW1C)
  [13] VBUSP_CFG_ECC_AGGR2_P2P_SRC_BUSECC_ENABLE_CLR — Interrupt Enable Clear Register for vbusp_cfg_ecc_aggr2_p2p_src_busecc_pend (access RW1C)
  [12] VBUSP_CFG_DSP4_P2P_SRC_BUSECC_ENABLE_CLR — Interrupt Enable Clear Register for vbusp_cfg_dsp4_p2p_src_busecc_pend (access RW1C)
  [11] MSMC_J7ES_GICSS_M2M_BRIDGE_DST_EDC_CTRL_BUSECC_ENABLE_CLR — Interrupt Enable Clear Register for msmc_gicss_m2m_bridge_dst_edc_ctrl_busecc_pend (access RW1C)
  [10] MSMC_J7ES_GICSS_M2M_BRIDGE_SRC_EDC_CTRL_BUSECC_ENABLE_CLR — Interrupt Enable Clear Register for msmc_gicss_m2m_bridge_src_edc_ctrl_busecc_pend (access RW1C)
  [9] DDRSS0_SRC_P2M_REASSEMBLY_BUSECC_ENABLE_CLR — Interrupt Enable Clear Register for ddrss0_src_p2m_reassembly_busecc_pend (access RW1C)
  [8] DDRSS0_SRC_P2M_BUSECC_ENABLE_CLR — Interrupt Enable Clear Register for ddrss0_src_p2m_busecc_pend (access RW1C)
  [7] DDRSS0_M2M_SRC_VBUSS_ENABLE_CLR — Interrupt Enable Clear Register for ddrss0_m2m_src_vbuss_pend (access RW1C)
  [6] VBUSP_DMSC_CBASS_EDC_CTRL_BUSECC_2_DUMMY_ENABLE_CLR — Interrupt Enable Clear Register for vbusp_dmsc_cbass_edc_ctrl_busecc_2_dummy_pend (access RW1C)
  [5] MSMC_J7ES_CFG_WRAP_CBASS_MSMC_J7ES_CFG_WRAP_CBASS_VBUSP_DDRSS0_P2P_BRIDGE_VBUSP_DDRSS0_BRIDGE_BUSECC_ENABLE_CLR — Interrupt Enable Clear Register for msmc_cfg_wrap_cbass_msmc_cfg_wrap_cbass_vbusp_ddrss0_p2p_bridge_vbusp_ddrss0_bridge_busecc_pend (access RW1C)
  [4] MSMC_J7ES_CFG_WRAP_CBASS_MSMC_J7ES_CFG_WRAP_CBASS_SCR1_SCR_MSMC_J7ES_CFG_WRAP_CBASS_SCR1_SCR_EDC_CTRL_BUSECC_2_DUMMY_ENABLE_CLR — Interrupt Enable Clear Register for msmc_cfg_wrap_cbass_msmc_cfg_wrap_cbass_scr1_scr_msmc_cfg_wrap_cbass_scr1_scr_edc_ctrl_busecc_2_dummy_pend (access RW1C)
  [3] MSMC_J7ES_CFG_WRAP_CBASS_MSMC_J7ES_CFG_WRAP_CBASS_VBUSP_GICSS_P2M_BRIDGE_VBUSP_GICSS_BRIDGE_REASSEMBLY_BUSECC_ENABLE_CLR — Interrupt Enable Clear Register for msmc_cfg_wrap_cbass_msmc_cfg_wrap_cbass_vbusp_gicss_p2m_bridge_vbusp_gicss_bridge_reassembly_busecc_pend (access RW1C)
  [2] MSMC_J7ES_CFG_WRAP_CBASS_MSMC_J7ES_CFG_WRAP_CBASS_VBUSP_GICSS_P2M_BRIDGE_VBUSP_GICSS_BRIDGE_BUSECC_ENABLE_CLR — Interrupt Enable Clear Register for msmc_cfg_wrap_cbass_msmc_cfg_wrap_cbass_vbusp_gicss_p2m_bridge_vbusp_gicss_bridge_busecc_pend (access RW1C)
  [1] EN_MSMC_P3_VBUSP_CFG_SRC_P2M_REASSEMBLY_BUSECC_DUMMY_ENABLE_CLR — Interrupt Enable Clear Register for en_msmc_p3_vbusp_cfg_src_p2m_reassembly_busecc_dummy_pend (access RW1C)
  [0] EN_MSMC_P2_VBUSP_CFG_SRC_P2M_REASSEMBLY_BUSECC_DUMMY_ENABLE_CLR — Interrupt Enable Clear Register for en_msmc_p2_vbusp_cfg_src_p2m_reassembly_busecc_dummy_pend (access RW1C)
0x53C MSMC_WRAP_ECC_DED_EOI_REG — EOI Register The EOI register is used to re-trigger the pulse interrupt signal to ensure that any nested interrupt events are serviced. The software interrupt handler must write to the EOI register at the end of the current interrupt processing routine, so that new events can re-trigger the pulse interrupt signal again. For level interrupt signals the EOI register is not functional and must not be used.
  [0] EOI_WR — EOI Register (access RW1S)
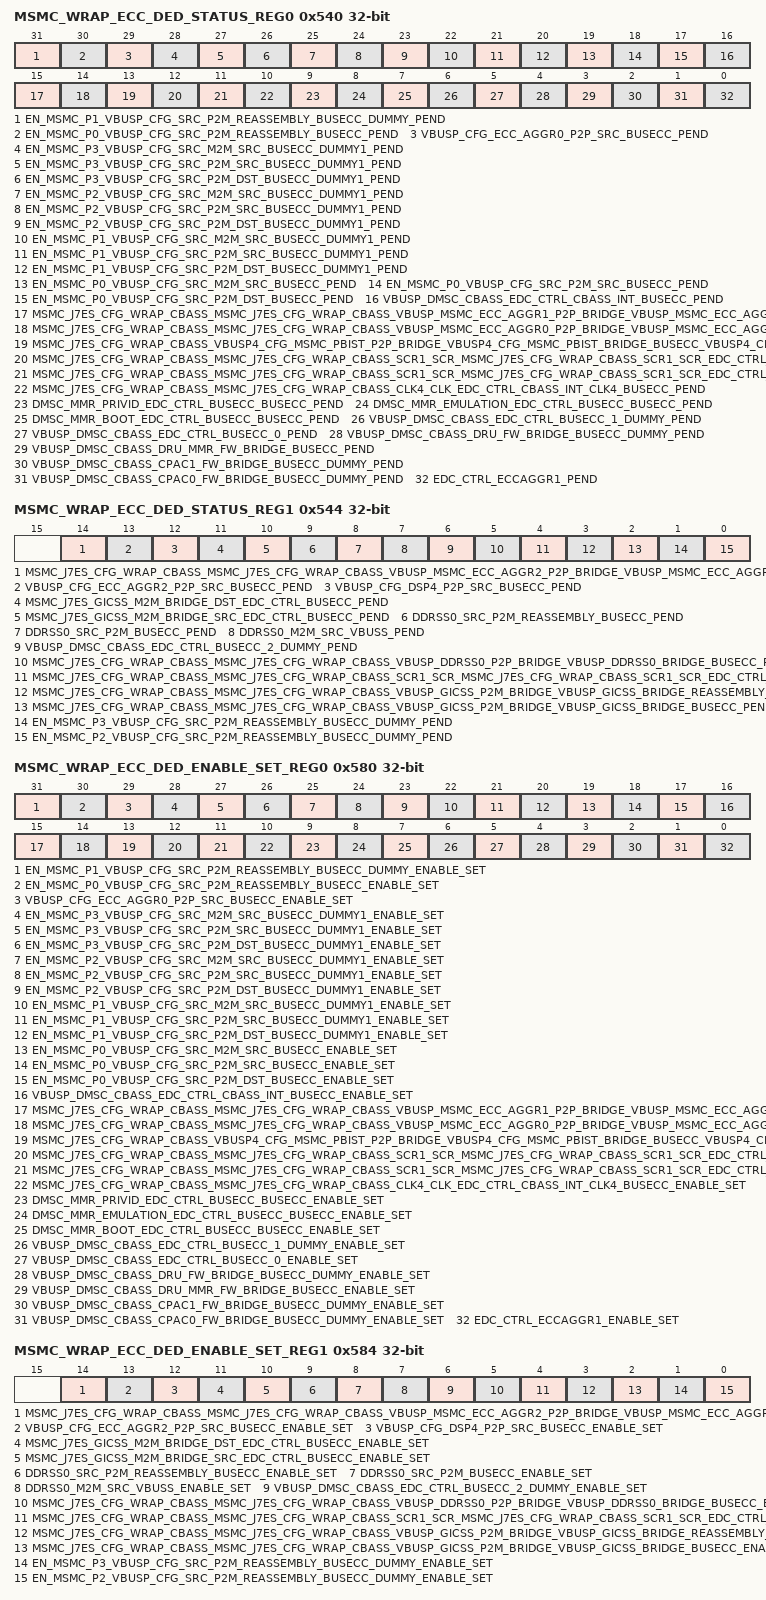
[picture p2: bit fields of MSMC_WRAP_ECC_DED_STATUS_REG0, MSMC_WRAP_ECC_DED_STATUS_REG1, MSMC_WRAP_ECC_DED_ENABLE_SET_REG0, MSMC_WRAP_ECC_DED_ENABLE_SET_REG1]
0x540 MSMC_WRAP_ECC_DED_STATUS_REG0 — Interrupt Status Register 0
  fields as MSMC_WRAP_ECC_SEC_STATUS_REG0
0x544 MSMC_WRAP_ECC_DED_STATUS_REG1 — Interrupt Status Register 1
  fields as MSMC_WRAP_ECC_SEC_STATUS_REG1
0x580 MSMC_WRAP_ECC_DED_ENABLE_SET_REG0 — Interrupt Enable Set Register 0
  fields as MSMC_WRAP_ECC_SEC_ENABLE_SET_REG0
0x584 MSMC_WRAP_ECC_DED_ENABLE_SET_REG1 — Interrupt Enable Set Register 1
  fields as MSMC_WRAP_ECC_SEC_ENABLE_SET_REG1
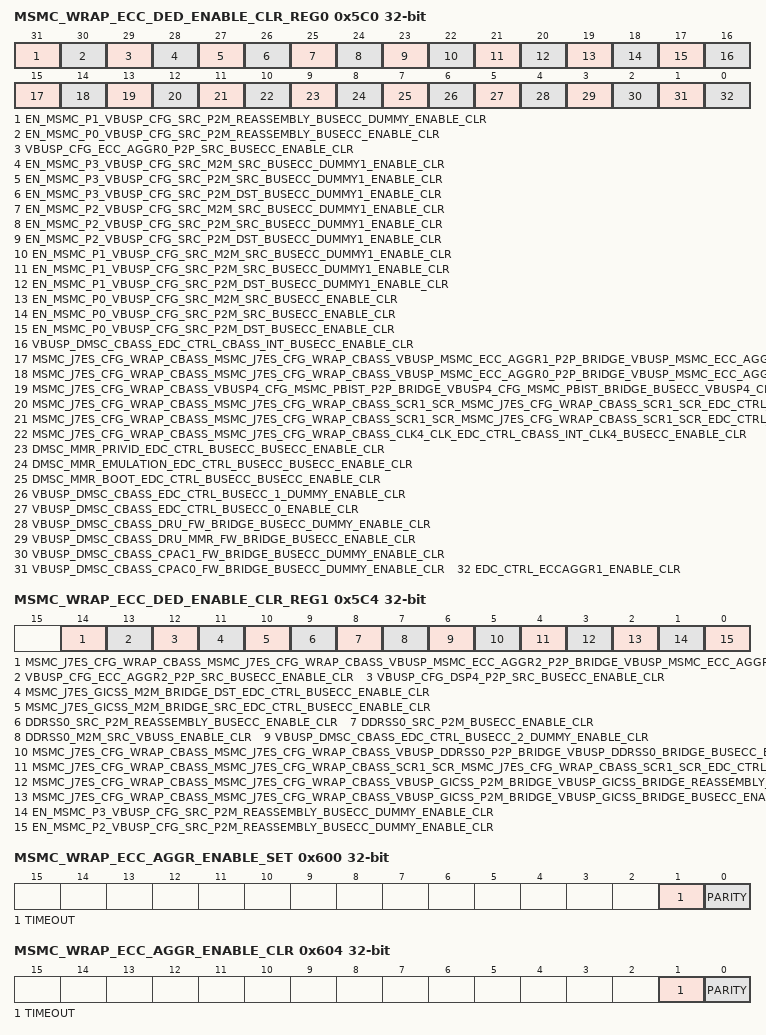
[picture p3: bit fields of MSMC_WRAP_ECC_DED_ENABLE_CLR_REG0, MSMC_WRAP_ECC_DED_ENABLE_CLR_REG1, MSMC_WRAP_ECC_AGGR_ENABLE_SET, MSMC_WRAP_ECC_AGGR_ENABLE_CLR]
0x5C0 MSMC_WRAP_ECC_DED_ENABLE_CLR_REG0 — Interrupt Enable Clear Register 0
  fields as MSMC_WRAP_ECC_SEC_ENABLE_CLR_REG0
0x5C4 MSMC_WRAP_ECC_DED_ENABLE_CLR_REG1 — Interrupt Enable Clear Register 1
  fields as MSMC_WRAP_ECC_SEC_ENABLE_CLR_REG1
0x600 MSMC_WRAP_ECC_AGGR_ENABLE_SET — AGGR interrupt enable set Register
  [1] TIMEOUT — interrupt enable set for svbus timeout errors (access RW1S)
  [0] PARITY — interrupt enable set for parity errors (access RW1S)
0x604 MSMC_WRAP_ECC_AGGR_ENABLE_CLR — AGGR interrupt enable clear Register
  [1] TIMEOUT — interrupt enable clear for svbus timeout errors (access RW1C)
  [0] PARITY — interrupt enable clear for parity errors (access RW1C)
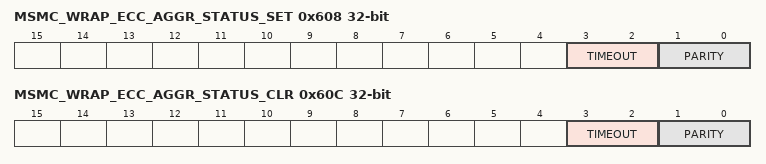
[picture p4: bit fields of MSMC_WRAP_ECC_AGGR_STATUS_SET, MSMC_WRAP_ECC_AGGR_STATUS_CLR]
0x608 MSMC_WRAP_ECC_AGGR_STATUS_SET — AGGR interrupt status set Register
  [3:2] TIMEOUT — interrupt status set for svbus timeout errors (access RWincr)
  [1:0] PARITY — interrupt status set for parity errors (access RWincr)
0x60C MSMC_WRAP_ECC_AGGR_STATUS_CLR — AGGR interrupt status clear Register
  [3:2] TIMEOUT — interrupt status clear for svbus timeout errors (access RWdecr)
  [1:0] PARITY — interrupt status clear for parity errors (access RWdecr)
